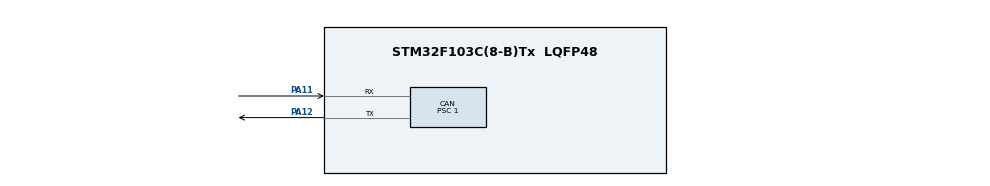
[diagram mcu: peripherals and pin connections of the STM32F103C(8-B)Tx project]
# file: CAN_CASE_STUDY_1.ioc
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CAN.BS1=CAN_BS1_6TQ
CAN.CalculateTimeBit=1000
CAN.CalculateTimeQuantum=125.0
CAN.Mode=CAN_MODE_LOOPBACK
CAN.Prescaler=1
Mcu.Family=STM32F1
Mcu.Name=STM32F103C(8-B)Tx
Mcu.Package=LQFP48
NVIC.PriorityGroup=NVIC_PRIORITYGROUP_4
PA11.Mode=Master
PA11.Signal=CAN_RX
PA12.Mode=Master
PA12.Signal=CAN_TX
PA13.Mode=Serial_Wire
PA13.Signal=SYS_JTMS-SWDIO
PA14.Mode=Serial_Wire
PA14.Signal=SYS_JTCK-SWCLK
ProjectManager.HeapSize=0x200
ProjectManager.StackSize=0x400
ProjectManager.TargetToolchain=MDK-ARM V5
RCC.APB1Freq_Value=8000000
RCC.APB2Freq_Value=8000000
board=custom

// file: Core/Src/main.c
/* USER CODE BEGIN Header */
/**
  ******************************************************************************
  * @file           : main.c
  * @brief          : Main program body
  ******************************************************************************
  * @attention
  *
  * <h2><center>&copy; Copyright (c) 2024 STMicroelectronics.
  * All rights reserved.</center></h2>
  *
  * This software component is licensed by ST under BSD 3-Clause license,
  * the "License"; You may not use this file except in compliance with the
  * License. You may obtain a copy of the License at:
  *                        opensource.org/licenses/BSD-3-Clause
  *
  ******************************************************************************
  */
/* USER CODE END Header */
#include "main.h"

CAN_HandleTypeDef hcan;

void SystemClock_Config(void);
static void MX_GPIO_Init(void);
static void MX_CAN_Init(void);

void CAN_TX(uint32_t ID , uint8_t DLC , uint8_t* payload)
{

	uint8_t pTxMailbox, numberFree_TxMailBox = 0;
	CAN_TxHeaderTypeDef pHeader ;
	pHeader.DLC = DLC;
	pHeader.IDE = CAN_ID_STD;
	pHeader.RTR = CAN_RTR_DATA;
	pHeader.StdId = ID;

	//Get Number of free Tx Mailboxes
	numberFree_TxMailBox = HAL_CAN_GetTxMailboxesFreeLevel(&hcan);
	if (numberFree_TxMailBox)
	{
		if(HAL_CAN_AddTxMessage(&hcan, &pHeader, payload, &pTxMailbox) != HAL_OK)
		{
			Error_Handler();
		}

		//wait until Tx Mailbox is transmitted (polling Mechanism)
		while(HAL_CAN_IsTxMessagePending(&hcan, pTxMailbox));

	}

}

int main(void)
{

  /* MCU Configuration--------------------------------------------------------*/

  /* Reset of all peripherals, Initializes the Flash interface and the Systick. */
  HAL_Init();

  /* Configure the system clock */
  SystemClock_Config();

  /* Initialize all configured peripherals */
  MX_GPIO_Init();
  MX_CAN_Init();

  //Start bxCAN --> Running state
  if(HAL_CAN_Start(&hcan)!= HAL_OK);
  {
	  Error_Handler();
  }

  uint8_t Tx_DATA[8] = {'C','A','N',' ','N','O',':',' '};
  uint8_t FrameNO = 0;

  /* Infinite loop */
  /* USER CODE BEGIN WHILE */
  while (1)
  {
	  Tx_DATA[7] = FrameNO++;

	  CAN_TX(0x3FF, 8, Tx_DATA); // wait until Tx is Done

    /* USER CODE END WHILE */

  }
}

void SystemClock_Config(void)
{
  RCC_OscInitTypeDef RCC_OscInitStruct = {0};
  RCC_ClkInitTypeDef RCC_ClkInitStruct = {0};

  /** Initializes the RCC Oscillators according to the specified parameters
  * in the RCC_OscInitTypeDef structure.
  */
  RCC_OscInitStruct.OscillatorType = RCC_OSCILLATORTYPE_HSI;
  RCC_OscInitStruct.HSIState = RCC_HSI_ON;
  RCC_OscInitStruct.HSICalibrationValue = RCC_HSICALIBRATION_DEFAULT;
  RCC_OscInitStruct.PLL.PLLState = RCC_PLL_NONE;
  if (HAL_RCC_OscConfig(&RCC_OscInitStruct) != HAL_OK)
  {
    Error_Handler();
  }
  /** Initializes the CPU, AHB and APB buses clocks
  */
  RCC_ClkInitStruct.ClockType = RCC_CLOCKTYPE_HCLK|RCC_CLOCKTYPE_SYSCLK
                              |RCC_CLOCKTYPE_PCLK1|RCC_CLOCKTYPE_PCLK2;
  RCC_ClkInitStruct.SYSCLKSource = RCC_SYSCLKSOURCE_HSI;
  RCC_ClkInitStruct.AHBCLKDivider = RCC_SYSCLK_DIV1;
  RCC_ClkInitStruct.APB1CLKDivider = RCC_HCLK_DIV1;
  RCC_ClkInitStruct.APB2CLKDivider = RCC_HCLK_DIV1;

  if (HAL_RCC_ClockConfig(&RCC_ClkInitStruct, FLASH_LATENCY_0) != HAL_OK)
  {
    Error_Handler();
  }
}

static void MX_CAN_Init(void)
{

  hcan.Instance = CAN1;
  hcan.Init.Prescaler = 1;
  hcan.Init.Mode = CAN_MODE_LOOPBACK;
  hcan.Init.SyncJumpWidth = CAN_SJW_1TQ;
  hcan.Init.TimeSeg1 = CAN_BS1_6TQ;
  hcan.Init.TimeSeg2 = CAN_BS2_1TQ;
  hcan.Init.TimeTriggeredMode = DISABLE;
  hcan.Init.AutoBusOff = DISABLE;
  hcan.Init.AutoWakeUp = DISABLE;
  hcan.Init.AutoRetransmission = ENABLE;
  hcan.Init.ReceiveFifoLocked = DISABLE;
  hcan.Init.TransmitFifoPriority = DISABLE;
  if (HAL_CAN_Init(&hcan) != HAL_OK)
  {
    Error_Handler();
  }

}

static void MX_GPIO_Init(void)
{

  /* GPIO Ports Clock Enable */
  __HAL_RCC_GPIOA_CLK_ENABLE();

}

void Error_Handler(void)
{
}

/************************ (C) COPYRIGHT STMicroelectronics *****END OF FILE****/
